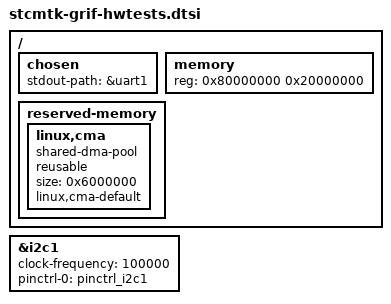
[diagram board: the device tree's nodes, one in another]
/dts-v1/;

#include <dt-bindings/input/input.h>
#include "imx6ull.dtsi"

/ {
	chosen {
		stdout-path = &uart1;
	};

	memory {
		reg = <0x80000000 0x20000000>;
	};

	reserved-memory {
		#address-cells = <1>;
		#size-cells = <1>;
		ranges;

		linux,cma {
			compatible = "shared-dma-pool";
			reusable;
			size = <0x6000000>;
			linux,cma-default;
		};
	};
};

&i2c1 {
	clock-frequency = <100000>;
	pinctrl-names = "default";
	pinctrl-0 = <&pinctrl_i2c1>;
	status = "okay";
};
